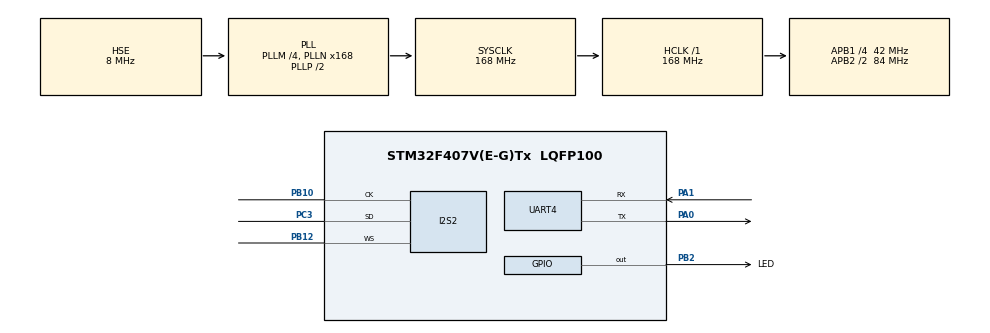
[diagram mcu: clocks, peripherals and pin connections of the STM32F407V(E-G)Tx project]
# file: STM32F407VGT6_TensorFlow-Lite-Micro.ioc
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Dma.Request0=SPI2_RX
Dma.SPI2_RX.0.Direction=DMA_PERIPH_TO_MEMORY
Dma.SPI2_RX.0.FIFOMode=DMA_FIFOMODE_DISABLE
Dma.SPI2_RX.0.Instance=DMA1_Stream3
Dma.SPI2_RX.0.MemDataAlignment=DMA_MDATAALIGN_HALFWORD
Dma.SPI2_RX.0.MemInc=DMA_MINC_ENABLE
Dma.SPI2_RX.0.Mode=DMA_CIRCULAR
Dma.SPI2_RX.0.PeriphDataAlignment=DMA_PDATAALIGN_HALFWORD
Dma.SPI2_RX.0.PeriphInc=DMA_PINC_DISABLE
Dma.SPI2_RX.0.Priority=DMA_PRIORITY_VERY_HIGH
I2S2.AudioFreq=I2S_AUDIOFREQ_16K
I2S2.CPOL=I2S_CPOL_HIGH
I2S2.DataFormat=I2S_DATAFORMAT_16B_EXTENDED
I2S2.ErrorAudioFreq=-0.26 %
I2S2.FullDuplexMode=I2S_FULLDUPLEXMODE_DISABLE
I2S2.Instance=SPI$Index
I2S2.Mode=I2S_MODE_MASTER_RX
I2S2.RealAudioFreq=15.957 KHz
I2S2.VirtualMode=I2S_MODE_MASTER
Mcu.Family=STM32F4
Mcu.Name=STM32F407V(E-G)Tx
Mcu.Package=LQFP100
NVIC.DMA1_Stream3_IRQn=true\:0\:0\:false\:false\:true\:false\:true\:true
NVIC.PriorityGroup=NVIC_PRIORITYGROUP_4
NVIC.UART4_IRQn=true\:0\:0\:false\:false\:true\:true\:true\:true
PA0-WKUP.Mode=Asynchronous
PA0-WKUP.Signal=UART4_TX
PA1.Mode=Asynchronous
PA1.Signal=UART4_RX
PA13.Mode=Serial_Wire
PA13.Signal=SYS_JTMS-SWDIO
PA14.Mode=Serial_Wire
PA14.Signal=SYS_JTCK-SWCLK
PB10.Mode=Half_Duplex_Master
PB10.Signal=I2S2_CK
PB12.Mode=Half_Duplex_Master
PB12.Signal=I2S2_WS
PB2.GPIO_Label=LED
PB2.Signal=GPIO_Output
PC3.Mode=Half_Duplex_Master
PC3.Signal=I2S2_SD
PH0-OSC_IN.Mode=HSE-External-Oscillator
PH0-OSC_IN.Signal=RCC_OSC_IN
PH1-OSC_OUT.Mode=HSE-External-Oscillator
PH1-OSC_OUT.Signal=RCC_OSC_OUT
ProjectManager.HeapSize=0x800
ProjectManager.StackSize=0x800
ProjectManager.TargetToolchain=CMake
RCC.48MHZClocksFreq_Value=84000000
RCC.AHBFreq_Value=168000000
RCC.APB1CLKDivider=RCC_HCLK_DIV4
RCC.APB1Freq_Value=42000000
RCC.APB1TimFreq_Value=84000000
RCC.APB2CLKDivider=RCC_HCLK_DIV2
RCC.APB2Freq_Value=84000000
RCC.APB2TimFreq_Value=168000000
RCC.CortexFreq_Value=168000000
RCC.HCLKFreq_Value=168000000
RCC.HSE_VALUE=8000000
RCC.HSI_VALUE=16000000
RCC.LSE_VALUE=32768
RCC.PLLM=4
RCC.PLLN=168
RCC.PLLSourceVirtual=RCC_PLLSOURCE_HSE
RCC.SYSCLKFreq_VALUE=168000000
RCC.SYSCLKSource=RCC_SYSCLKSOURCE_PLLCLK
RCC.VCOOutputFreq_Value=336000000
STMicroelectronics.X-CUBE-AI.10.2.0.ActivationBufferSizeList=34916
STMicroelectronics.X-CUBE-AI.10.2.0.ActivationBuffers=pool0
STMicroelectronics.X-CUBE-AI.10.2.0.ActivationNames=pool0
STMicroelectronics.X-CUBE-AI.10.2.0.ActivationSizes=AI_MICRO_SPEECH_DATA_ACTIVATION_1_SIZE
STMicroelectronics.X-CUBE-AI.10.2.0.ApplicationCcDeviceJjApplication=ApplicationTemplate
STMicroelectronics.X-CUBE-AI.10.2.0.HeapSize=0x800
STMicroelectronics.X-CUBE-AI.10.2.0.InternalRamActivationBufferMaxSize=AI_MICRO_SPEECH_DATA_ACTIVATIONS_SIZE
STMicroelectronics.X-CUBE-AI.10.2.0.LatestDirectoryUsed-643e04092900c1dfc440b992d5651452d067f13695986b17a0e141a5033e2e3c=D\:\\edgedownload\\STM32F407VGT6_TensorFlow-Lite-Micro\\stm32f4_tflm_project\\examples\\micro_speech\\models\\models_cmsis
STMicroelectronics.X-CUBE-AI.10.2.0.MaximumNumberOfInputLayer=1
STMicroelectronics.X-CUBE-AI.10.2.0.MaximumNumberOfOutputLayer=1
STMicroelectronics.X-CUBE-AI.10.2.0.MaximumSizeOfInputLayer=1
STMicroelectronics.X-CUBE-AI.10.2.0.MaximumSizeOfOutputLayer=1
STMicroelectronics.X-CUBE-AI.10.2.0.ModelActualCompression-643e04092900c1dfc440b992d5651452d067f13695986b17a0e141a5033e2e3c=0.0
STMicroelectronics.X-CUBE-AI.10.2.0.ModelCompression-643e04092900c1dfc440b992d5651452d067f13695986b17a0e141a5033e2e3c=None
STMicroelectronics.X-CUBE-AI.10.2.0.ModelFlashOccupation-643e04092900c1dfc440b992d5651452d067f13695986b17a0e141a5033e2e3c=0
STMicroelectronics.X-CUBE-AI.10.2.0.ModelHashList=643e04092900c1dfc440b992d5651452d067f13695986b17a0e141a5033e2e3c
STMicroelectronics.X-CUBE-AI.10.2.0.ModelKind-643e04092900c1dfc440b992d5651452d067f13695986b17a0e141a5033e2e3c=TFLITE
STMicroelectronics.X-CUBE-AI.10.2.0.ModelMacc-643e04092900c1dfc440b992d5651452d067f13695986b17a0e141a5033e2e3c=0
STMicroelectronics.X-CUBE-AI.10.2.0.ModelName-643e04092900c1dfc440b992d5651452d067f13695986b17a0e141a5033e2e3c=micro_speech
STMicroelectronics.X-CUBE-AI.10.2.0.ModelNameList=micro_speech
STMicroelectronics.X-CUBE-AI.10.2.0.ModelRamOccupation-643e04092900c1dfc440b992d5651452d067f13695986b17a0e141a5033e2e3c=0
STMicroelectronics.X-CUBE-AI.10.2.0.ModelStructureFile-643e04092900c1dfc440b992d5651452d067f13695986b17a0e141a5033e2e3c=stm32f4_tflm_project/examples/micro_speech/models/models_cmsis/model.tflite
STMicroelectronics.X-CUBE-AI.10.2.0.ModelType-643e04092900c1dfc440b992d5651452d067f13695986b17a0e141a5033e2e3c=STM32Cube.AI MCU runtime
STMicroelectronics.X-CUBE-AI.10.2.0.ReadyForCodeGeneration=true
STMicroelectronics.X-CUBE-AI.10.2.0.StackSize=0x800
STMicroelectronics.X-CUBE-AI.10.2.0.WorkingBufferStartAddrList=0xFFFFFFFF
STMicroelectronics.X-CUBE-AI.10.2.0.XAaCUBEAaAICcArtificialOoIntelligenceJjCore=true
STMicroelectronics.X-CUBE-AI.10.2.0.copyWeightToRam=false
STMicroelectronics.X-CUBE-AI.10.2.0.copyWeightToRam-643e04092900c1dfc440b992d5651452d067f13695986b17a0e141a5033e2e3c=false
STMicroelectronics.X-CUBE-AI.10.2.0.customLayerConfigEnabled=false
STMicroelectronics.X-CUBE-AI.10.2.0.customLayerConfigEnabled-643e04092900c1dfc440b992d5651452d067f13695986b17a0e141a5033e2e3c=false
STMicroelectronics.X-CUBE-AI.10.2.0.noOnnxIoTranspose=false
STMicroelectronics.X-CUBE-AI.10.2.0.noOnnxIoTranspose-643e04092900c1dfc440b992d5651452d067f13695986b17a0e141a5033e2e3c=false
STMicroelectronics.X-CUBE-AI.10.2.0.useInputAllocation=true
STMicroelectronics.X-CUBE-AI.10.2.0.useInputAllocation-643e04092900c1dfc440b992d5651452d067f13695986b17a0e141a5033e2e3c=true
STMicroelectronics.X-CUBE-AI.10.2.0.useOutputAllocation=true
STMicroelectronics.X-CUBE-AI.10.2.0.useOutputAllocation-643e04092900c1dfc440b992d5651452d067f13695986b17a0e141a5033e2e3c=true
UART4.VirtualMode=Asynchronous
VP_STMicroelectronics.X-CUBE-AI_VS_ArtificialOoIntelligenceJjXAaCUBEAaAI_10.2.0.Mode=ArtificialOoIntelligenceJjXAaCUBEAaAI
VP_STMicroelectronics.X-CUBE-AI_VS_DeviceJjApplication_10.2.0.Mode=DeviceJjApplication
board=custom

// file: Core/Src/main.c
/* USER CODE BEGIN Header */
/**
 ******************************************************************************
 * @file           : main.c
 * @brief          : Main program body
 ******************************************************************************
 * @attention
 *
 * Copyright (c) 2026 STMicroelectronics.
 * All rights reserved.
 *
 * This software is licensed under terms that can be found in the LICENSE file
 * in the root directory of this software component.
 * If no LICENSE file comes with this software, it is provided AS-IS.
 *
 ******************************************************************************
 */
/* USER CODE END Header */
#include "main.h"
#include "dma.h"
#include "i2s.h"
#include "usart.h"
#include "gpio.h"
#include "app_x-cube-ai.h"

/* USER CODE BEGIN Includes */
#include "stdio.h"
#include "audio_stream.h"
/* USER CODE END Includes */

void SystemClock_Config(void);

int main(void)
{

  /* MCU Configuration--------------------------------------------------------*/

  /* Reset of all peripherals, Initializes the Flash interface and the Systick. */
  HAL_Init();

  /* Configure the system clock */
  SystemClock_Config();

  /* Initialize all configured peripherals */
  MX_GPIO_Init();
  MX_DMA_Init();
  MX_UART4_Init();
  MX_I2S2_Init();
  MX_X_CUBE_AI_Init();
  /* USER CODE BEGIN 2 */
  AudioStream_init();
  AudioStream_start();
  /* USER CODE END 2 */

  /* Infinite loop */
  while (1)
  {

  MX_X_CUBE_AI_Process();
    /* USER CODE BEGIN 3 */
    // HAL_GPIO_TogglePin(LED_GPIO_Port, LED_Pin);
    // HAL_Delay(1);
  }
  /* USER CODE END 3 */
}

void SystemClock_Config(void)
{
  RCC_OscInitTypeDef RCC_OscInitStruct = {0};
  RCC_ClkInitTypeDef RCC_ClkInitStruct = {0};

  /** Configure the main internal regulator output voltage
  */
  __HAL_RCC_PWR_CLK_ENABLE();
  __HAL_PWR_VOLTAGESCALING_CONFIG(PWR_REGULATOR_VOLTAGE_SCALE1);

  /** Initializes the RCC Oscillators according to the specified parameters
  * in the RCC_OscInitTypeDef structure.
  */
  RCC_OscInitStruct.OscillatorType = RCC_OSCILLATORTYPE_HSE;
  RCC_OscInitStruct.HSEState = RCC_HSE_ON;
  RCC_OscInitStruct.PLL.PLLState = RCC_PLL_ON;
  RCC_OscInitStruct.PLL.PLLSource = RCC_PLLSOURCE_HSE;
  RCC_OscInitStruct.PLL.PLLM = 4;
  RCC_OscInitStruct.PLL.PLLN = 168;
  RCC_OscInitStruct.PLL.PLLP = RCC_PLLP_DIV2;
  RCC_OscInitStruct.PLL.PLLQ = 4;
  if (HAL_RCC_OscConfig(&RCC_OscInitStruct) != HAL_OK)
  {
    Error_Handler();
  }

  /** Initializes the CPU, AHB and APB buses clocks
  */
  RCC_ClkInitStruct.ClockType = RCC_CLOCKTYPE_HCLK|RCC_CLOCKTYPE_SYSCLK
                              |RCC_CLOCKTYPE_PCLK1|RCC_CLOCKTYPE_PCLK2;
  RCC_ClkInitStruct.SYSCLKSource = RCC_SYSCLKSOURCE_PLLCLK;
  RCC_ClkInitStruct.AHBCLKDivider = RCC_SYSCLK_DIV1;
  RCC_ClkInitStruct.APB1CLKDivider = RCC_HCLK_DIV4;
  RCC_ClkInitStruct.APB2CLKDivider = RCC_HCLK_DIV2;

  if (HAL_RCC_ClockConfig(&RCC_ClkInitStruct, FLASH_LATENCY_5) != HAL_OK)
  {
    Error_Handler();
  }
}

void Error_Handler(void)
{
  __disable_irq();
  while (1)
  {
  }
}
